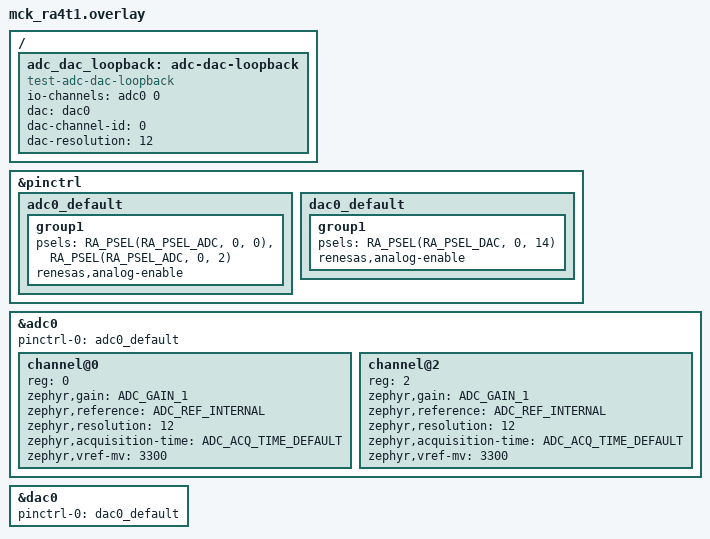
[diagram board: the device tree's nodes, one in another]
/*
 * Copyright (c) 2025 Renesas Electronics Corporation
 *
 * SPDX-License-Identifier: Apache-2.0
 */

#include <zephyr/dt-bindings/adc/adc.h>

&pinctrl {
	adc0_default: adc0_default {
		group1 {
			psels = <RA_PSEL(RA_PSEL_ADC, 0, 0)>,
				<RA_PSEL(RA_PSEL_ADC, 0, 2)>;
			renesas,analog-enable;
		};
	};

	dac0_default: dac0_default {
		group1 {
			/* output */
			psels = <RA_PSEL(RA_PSEL_DAC, 0, 14)>;
			renesas,analog-enable;
		};
	};
};

&adc0 {
	#address-cells = <1>;
	#size-cells = <0>;
	pinctrl-0 = <&adc0_default>;
	pinctrl-names = "default";
	status = "okay";

	channel@0 {
		reg = <0>;
		zephyr,gain = "ADC_GAIN_1";
		zephyr,reference = "ADC_REF_INTERNAL";
		zephyr,resolution = <12>;
		zephyr,acquisition-time = <ADC_ACQ_TIME_DEFAULT>;
		zephyr,vref-mv = <3300>;
	};

	channel@2 {
		reg = <2>;
		zephyr,gain = "ADC_GAIN_1";
		zephyr,reference = "ADC_REF_INTERNAL";
		zephyr,resolution = <12>;
		zephyr,acquisition-time = <ADC_ACQ_TIME_DEFAULT>;
		zephyr,vref-mv = <3300>;
	};
};

&dac0 {
	pinctrl-0 = <&dac0_default>;
	pinctrl-names = "default";
	status = "okay";
};

/ {
	adc_dac_loopback: adc-dac-loopback {
		compatible = "test-adc-dac-loopback";
		io-channels = <&adc0 0>;
		dac = <&dac0>;
		dac-channel-id = <0>;
		dac-resolution = <12>;
	};
};
